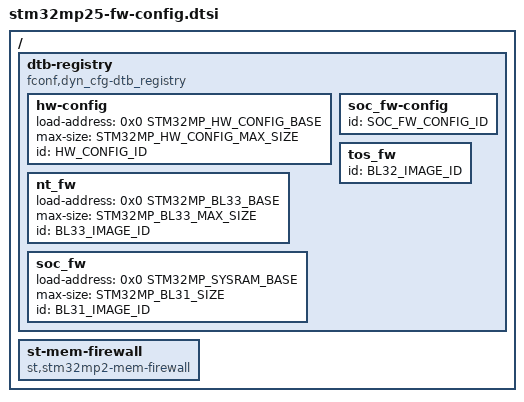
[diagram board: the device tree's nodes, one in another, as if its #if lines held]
// SPDX-License-Identifier: (GPL-2.0-only OR BSD-3-Clause)
/*
 * Copyright (c) 2024-2026, STMicroelectronics - All Rights Reserved
 */

#include <common/tbbr/tbbr_img_def.h>

#include <platform_def.h>

/dts-v1/;

/ {
	dtb-registry {
		compatible = "fconf,dyn_cfg-dtb_registry";

#if !STM32MP_SEC_APP_FW
		hw-config {
			load-address = <0x0 STM32MP_HW_CONFIG_BASE>;
			max-size = <STM32MP_HW_CONFIG_MAX_SIZE>;
			id = <HW_CONFIG_ID>;
		};

		nt_fw {
			load-address = <0x0 STM32MP_BL33_BASE>;
			max-size = <STM32MP_BL33_MAX_SIZE>;
			id = <BL33_IMAGE_ID>;
		};
#endif

		soc_fw {
			load-address = <0x0 STM32MP_SYSRAM_BASE>;
			max-size = <STM32MP_BL31_SIZE>;
			id = <BL31_IMAGE_ID>;
		};

		soc_fw-config {
			id = <SOC_FW_CONFIG_ID>;
		};

		tos_fw {
			id = <BL32_IMAGE_ID>;
		};
	};

	st-mem-firewall {
		compatible = "st,stm32mp2-mem-firewall";
		#address-cells = <2>;
		#size-cells = <2>;
	};
};
